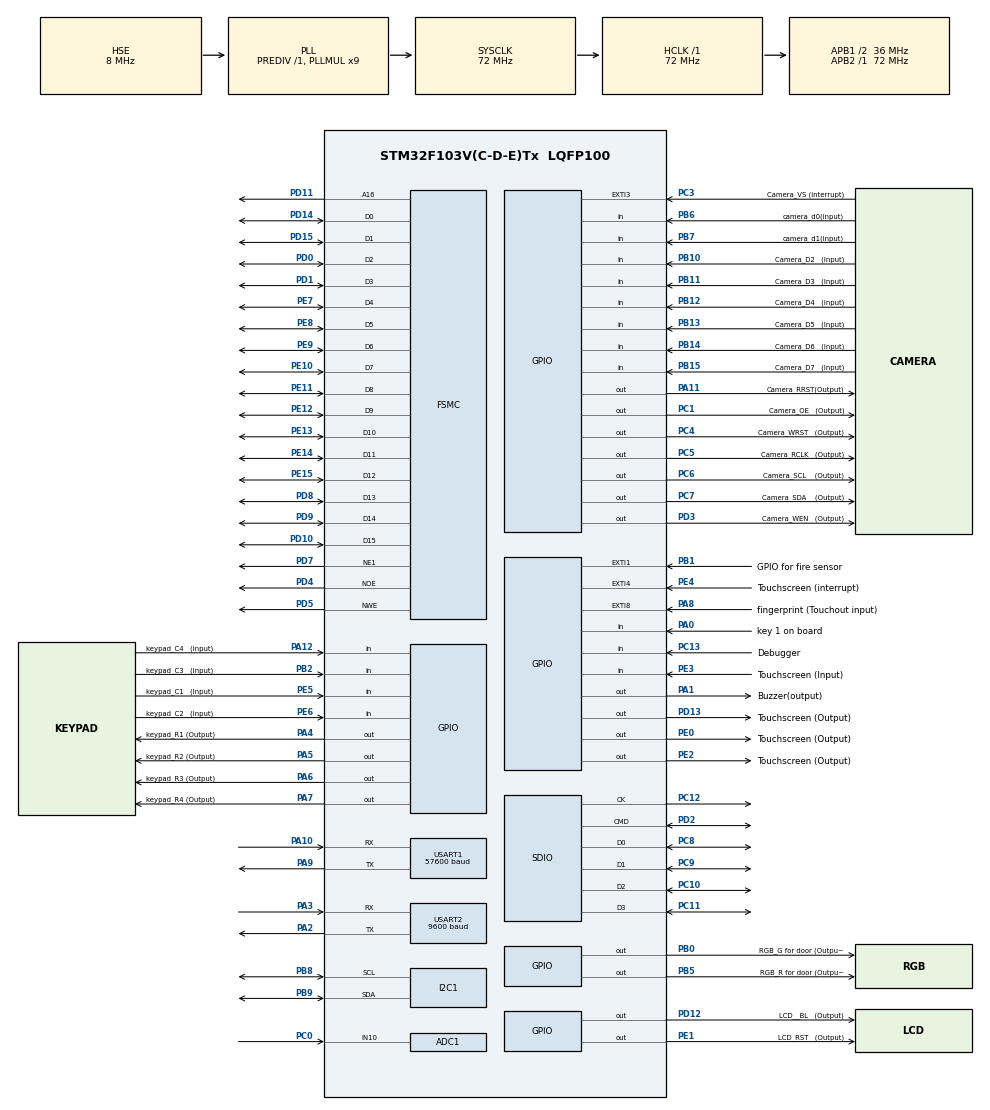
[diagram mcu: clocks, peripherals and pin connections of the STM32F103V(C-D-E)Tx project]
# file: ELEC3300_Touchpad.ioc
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ADC1.Channel-0\#ChannelRegularConversion=ADC_CHANNEL_10
ADC1.ContinuousConvMode=ENABLE
ADC1.EnableAnalogWatchDog=false
ADC1.NbrOfConversionFlag=1
ADC1.Rank-0\#ChannelRegularConversion=1
ADC1.SamplingTime-0\#ChannelRegularConversion=ADC_SAMPLETIME_55CYCLES_5
ADC1.master=1
FATFS._MAX_SS=4096
Mcu.Family=STM32F1
Mcu.Name=STM32F103V(C-D-E)Tx
Mcu.Package=LQFP100
NVIC.EXTI1_IRQn=true\:0\:0\:false\:false\:true\:true\:true
NVIC.EXTI3_IRQn=true\:0\:0\:false\:false\:true\:true\:true
NVIC.EXTI4_IRQn=true\:0\:0\:false\:false\:true\:true\:true
NVIC.EXTI9_5_IRQn=true\:1\:0\:true\:false\:true\:true\:true
NVIC.PriorityGroup=NVIC_PRIORITYGROUP_4
OSC_IN.Mode=HSE-External-Oscillator
OSC_IN.Signal=RCC_OSC_IN
OSC_OUT.Mode=HSE-External-Oscillator
OSC_OUT.Signal=RCC_OSC_OUT
PA0-WKUP.GPIO_Label=key 1 on board
PA0-WKUP.Signal=GPIO_Input
PA1.GPIO_Label=Buzzer(output)
PA1.GPIO_ModeDefaultOutputPP=GPIO_MODE_OUTPUT_PP
PA1.GPIO_PuPd=GPIO_NOPULL
PA1.GPIO_Speed=GPIO_SPEED_FREQ_HIGH
PA1.Signal=GPIO_Output
PA10.Mode=Asynchronous
PA10.Signal=USART1_RX
PA11.GPIO_Label=Camera_RRST(Output)
PA11.GPIO_Speed=GPIO_SPEED_FREQ_HIGH
PA11.PinState=GPIO_PIN_RESET
PA11.Signal=GPIO_Output
PA12.GPIO_Label=keypad_C4   (Input)
PA12.GPIO_PuPd=GPIO_PULLUP
PA12.Signal=GPIO_Input
PA13.Mode=Serial_Wire
PA13.Signal=SYS_JTMS-SWDIO
PA14.Mode=Serial_Wire
PA14.Signal=SYS_JTCK-SWCLK
PA2.Mode=Asynchronous
PA2.Signal=USART2_TX
PA3.Mode=Asynchronous
PA3.Signal=USART2_RX
PA4.GPIO_Label=keypad_R1 (Output)
PA4.Signal=GPIO_Output
PA5.GPIO_Label=keypad_R2 (Output)
PA5.Signal=GPIO_Output
PA6.GPIO_Label=keypad_R3 (Output)
PA6.Signal=GPIO_Output
PA7.GPIO_Label=keypad_R4 (Output)
PA7.Signal=GPIO_Output
PA8.GPIO_Label=fingerprint (Touchout input)
PA8.Signal=GPXTI8
PA9.Mode=Asynchronous
PA9.Signal=USART1_TX
PB0.GPIO_Label=RGB_G for door (Output)
PB0.GPIO_Speed=GPIO_SPEED_FREQ_HIGH
PB0.Signal=GPIO_Output
PB1.GPIO_Label=GPIO for fire sensor
PB1.GPIO_ModeDefaultEXTI=GPIO_MODE_IT_RISING_FALLING
PB1.Signal=GPXTI1
PB10.GPIO_Label=Camera_D2   (Input)
PB10.Signal=GPIO_Input
PB11.GPIO_Label=Camera_D3   (Input)
PB11.Signal=GPIO_Input
PB12.GPIO_Label=Camera_D4   (Input)
PB12.Signal=GPIO_Input
PB13.GPIO_Label=Camera_D5   (Input)
PB13.Signal=GPIO_Input
PB14.GPIO_Label=Camera_D6   (Input)
PB14.Signal=GPIO_Input
PB15.GPIO_Label=Camera_D7   (Input)
PB15.Signal=GPIO_Input
PB2.GPIO_Label=keypad_C3   (Input)
PB2.GPIO_PuPd=GPIO_PULLUP
PB2.Signal=GPIO_Input
PB5.GPIO_Label=RGB_R for door (Output)
PB5.GPIO_Speed=GPIO_SPEED_FREQ_HIGH
PB5.Signal=GPIO_Output
PB6.GPIO_Label=camera_d0(input)
PB6.Signal=GPIO_Input
PB7.GPIO_Label=camera_d1(input)
PB7.Signal=GPIO_Input
PB8.Mode=I2C
PB8.Signal=I2C1_SCL
PB9.Mode=I2C
PB9.Signal=I2C1_SDA
PC0.Signal=ADCx_IN10
PC1.GPIO_Label=Camera_OE   (Output)
PC1.GPIO_Speed=GPIO_SPEED_FREQ_HIGH
PC1.Signal=GPIO_Output
PC10.Mode=SD_4_bits_Wide_bus
PC10.Signal=SDIO_D2
PC11.Mode=SD_4_bits_Wide_bus
PC11.Signal=SDIO_D3
PC12.Mode=SD_4_bits_Wide_bus
PC12.Signal=SDIO_CK
PC13-TAMPER-RTC.GPIO_Label=Debugger
PC13-TAMPER-RTC.GPIO_PuPd=GPIO_NOPULL
PC13-TAMPER-RTC.Signal=GPIO_Input
PC14-OSC32_IN.Mode=LSE-External-Oscillator
PC14-OSC32_IN.Signal=RCC_OSC32_IN
PC15-OSC32_OUT.Mode=LSE-External-Oscillator
PC15-OSC32_OUT.Signal=RCC_OSC32_OUT
PC3.GPIO_Label=Camera_VS (interrupt)
PC3.GPIO_ModeDefaultEXTI=GPIO_MODE_IT_FALLING
PC3.Signal=GPXTI3
PC4.GPIO_Label=Camera_WRST   (Output)
PC4.GPIO_Speed=GPIO_SPEED_FREQ_HIGH
PC4.Signal=GPIO_Output
PC5.GPIO_Label=Camera_RCLK   (Output)
PC5.GPIO_Speed=GPIO_SPEED_FREQ_HIGH
PC5.Signal=GPIO_Output
PC6.GPIO_Label=Camera_SCL    (Output)
PC6.GPIO_ModeDefaultOutputPP=GPIO_MODE_OUTPUT_OD
PC6.GPIO_PuPd=GPIO_NOPULL
PC6.GPIO_Speed=GPIO_SPEED_FREQ_HIGH
PC6.Signal=GPIO_Output
PC7.GPIO_Label=Camera_SDA    (Output)
PC7.GPIO_ModeDefaultOutputPP=GPIO_MODE_OUTPUT_OD
PC7.GPIO_Speed=GPIO_SPEED_FREQ_HIGH
PC7.Signal=GPIO_Output
PC8.Mode=SD_4_bits_Wide_bus
PC8.Signal=SDIO_D0
PC9.Mode=SD_4_bits_Wide_bus
PC9.Signal=SDIO_D1
PD0.Mode=16b-d1
PD0.Signal=FSMC_D2
PD1.Mode=16b-d1
PD1.Signal=FSMC_D3
PD10.Mode=16b-d1
PD10.Signal=FSMC_D15
PD11.Mode=A16_1
PD11.Signal=FSMC_A16
PD12.GPIO_Label=LCD__BL   (Output)
PD12.GPIO_Speed=GPIO_SPEED_FREQ_HIGH
PD12.PinState=GPIO_PIN_RESET
PD12.Signal=GPIO_Output
PD13.GPIO_Label=Touchscreen (Output)
PD13.GPIO_Speed=GPIO_SPEED_FREQ_HIGH
PD13.Signal=GPIO_Output
PD14.Mode=16b-d1
PD14.Signal=FSMC_D0
PD15.Mode=16b-d1
PD15.Signal=FSMC_D1
PD2.Mode=SD_4_bits_Wide_bus
PD2.Signal=SDIO_CMD
PD3.GPIO_Label=Camera_WEN   (Output)
PD3.GPIO_Speed=GPIO_SPEED_FREQ_HIGH
PD3.Signal=GPIO_Output
PD4.Mode=Lcd1
PD4.Signal=FSMC_NOE
PD5.Mode=Lcd1
PD5.Signal=FSMC_NWE
PD7.Mode=NorPsramChipSelect1_1
PD7.Signal=FSMC_NE1
PD8.Mode=16b-d1
PD8.Signal=FSMC_D13
PD9.Mode=16b-d1
PD9.Signal=FSMC_D14
PE0.GPIO_Label=Touchscreen (Output)
PE0.GPIO_Speed=GPIO_SPEED_FREQ_HIGH
PE0.Signal=GPIO_Output
PE1.GPIO_Label=LCD_RST   (Output)
PE1.GPIO_Speed=GPIO_SPEED_FREQ_HIGH
PE1.PinState=GPIO_PIN_RESET
PE1.Signal=GPIO_Output
PE10.Mode=16b-d1
PE10.Signal=FSMC_D7
PE11.Mode=16b-d1
PE11.Signal=FSMC_D8
PE12.Mode=16b-d1
PE12.Signal=FSMC_D9
PE13.Mode=16b-d1
PE13.Signal=FSMC_D10
PE14.Mode=16b-d1
PE14.Signal=FSMC_D11
PE15.Mode=16b-d1
PE15.Signal=FSMC_D12
PE2.GPIO_Label=Touchscreen (Output)
PE2.GPIO_Speed=GPIO_SPEED_FREQ_HIGH
PE2.Signal=GPIO_Output
PE3.GPIO_Label=Touchscreen (Input)
PE3.GPIO_PuPd=GPIO_PULLUP
PE3.Signal=GPIO_Input
PE4.GPIO_Label=Touchscreen (interrupt)
PE4.GPIO_ModeDefaultEXTI=GPIO_MODE_IT_FALLING
PE4.GPIO_PuPd=GPIO_PULLUP
PE4.Signal=GPXTI4
PE5.GPIO_Label=keypad_C1   (Input)
PE5.GPIO_PuPd=GPIO_PULLUP
PE5.Signal=GPIO_Input
PE6.GPIO_Label=keypad_C2   (Input)
PE6.GPIO_PuPd=GPIO_PULLUP
PE6.Signal=GPIO_Input
PE7.Mode=16b-d1
PE7.Signal=FSMC_D4
PE8.Mode=16b-d1
PE8.Signal=FSMC_D5
PE9.Mode=16b-d1
PE9.Signal=FSMC_D6
ProjectManager.HeapSize=0x200
ProjectManager.StackSize=0x400
ProjectManager.TargetToolchain=MDK-ARM V5
RCC.ADCPresc=RCC_ADCPCLK2_DIV6
RCC.AHBFreq_Value=72000000
RCC.APB1CLKDivider=RCC_HCLK_DIV2
RCC.APB1Freq_Value=36000000
RCC.APB1TimFreq_Value=72000000
RCC.APB2Freq_Value=72000000
RCC.APB2TimFreq_Value=72000000
RCC.HCLKFreq_Value=72000000
RCC.PLLMUL=RCC_PLL_MUL9
RCC.PLLSourceVirtual=RCC_PLLSOURCE_HSE
RCC.SYSCLKFreq_VALUE=72000000
RCC.SYSCLKSource=RCC_SYSCLKSOURCE_PLLCLK
RCC.USBFreq_Value=72000000
SDIO.ClockDiv=4
SH.ADCx_IN10.0=ADC1_IN10,IN10
USART1.BaudRate=57600
USART1.StopBits=STOPBITS_1
USART1.VirtualMode=VM_ASYNC
USART2.BaudRate=9600
USART2.VirtualMode=VM_ASYNC
VP_FATFS_VS_SDIO.Mode=SDIO
board=custom

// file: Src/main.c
/* USER CODE BEGIN Header */
/**
  ******************************************************************************
  * @file           : main.c
  * @brief          : Main program body
  ******************************************************************************
  * @attention
  *
  * <h2><center>&copy; Copyright (c) 2022 STMicroelectronics.
  * All rights reserved.</center></h2>
  *
  * This software component is licensed by ST under Ultimate Liberty license
  * SLA0044, the "License"; You may not use this file except in compliance with
  * the License. You may obtain a copy of the License at:
  *                             www.st.com/SLA0044
  *
  ******************************************************************************
  */
/* USER CODE END Header */

#include "main.h"
#include "fatfs.h"

/* USER CODE BEGIN Includes */
#include "own_define_functions.h"
#include "as608.h"
#include <stdlib.h>
/* USER CODE END Includes */

ADC_HandleTypeDef hadc1;

I2C_HandleTypeDef hi2c1;

SD_HandleTypeDef hsd;

UART_HandleTypeDef huart1;
UART_HandleTypeDef huart2;

SRAM_HandleTypeDef hsram1;

/* USER CODE BEGIN PV */
volatile uint8_t FR_state = 0x00;
uint16_t current_id = 0x00;
/* USER CODE END PV */

void SystemClock_Config(void);
static void MX_GPIO_Init(void);
static void MX_FSMC_Init(void);
static void MX_SDIO_SD_Init(void);
static void MX_ADC1_Init(void);
static void MX_USART1_UART_Init(void);
static void MX_I2C1_Init(void);
static void MX_USART2_UART_Init(void);

int main(void)
{

  /* MCU Configuration--------------------------------------------------------*/

  /* Reset of all peripherals, Initializes the Flash interface and the Systick. */
  HAL_Init();

  /* Configure the system clock */
  SystemClock_Config();

  /* Initialize all configured peripherals */
  MX_GPIO_Init();
  MX_FSMC_Init();
  MX_SDIO_SD_Init();
  MX_FATFS_Init();
  MX_ADC1_Init();
  MX_USART1_UART_Init();
  MX_I2C1_Init();
  MX_USART2_UART_Init();
  /* USER CODE BEGIN 2 */
	macXPT2046_CS_DISABLE();
	delete_ALL();

	LCD_INIT();

	HAL_GPIO_WritePin(GPIOB, GPIO_PIN_0,GPIO_PIN_SET); // green off
	HAL_GPIO_WritePin(GPIOB, GPIO_PIN_5,GPIO_PIN_RESET); // red on

	//start page
	LCD_DrawString_Color(30, 100, "Home Protecting System", BACKGROUND, BLUE);
	HAL_Delay(4000);

	while( ! XPT2046_Touch_Calibrate () );   //calibrate TouchPad
	LCD_GramScan ( 1 );

	//set the password first
	LCD_Clear(0, 0, 240, 320, WHITE);
	LCD_DrawString_Color(10,10,"Please set a password with 4 places :", BACKGROUND, BLUE);
	enterPassword(password);
	LCD_DrawString_Color(10,150,"Password successfully set", BACKGROUND, BLUE);
	HAL_Delay(2000);

	//draw homepage
	LCD_homepage();
  /* USER CODE END 2 */

  /* Infinite loop */
  /* USER CODE BEGIN WHILE */
	//start co sensor in adc1
	HAL_ADCEx_Calibration_Start(&hadc1);
	HAL_ADC_Start(&hadc1);
	HAL_ADC_PollForConversion(&hadc1, 1000);

	while (1)
  {
		//if flame sensor detect flame. interrupt
		//if fingerprint sensor detect finger, interrupt

		//detect CO level in air, using polling
		CO_detect();
		//if user trigger #, check the password
		if(read_keypad() == '#'){
			verifyPassword(password, password_enter, &photoNum, &door_status);
			HAL_Delay(2000);
			LCD_homepage();
			continue;
		}

		//check homepage buttons
		if( ucXPT2046_TouchFlag == 1 ){
			check_homepage();
			ucXPT2046_TouchFlag = 0;
    }

		//close door after open for a while
		if (door_status == 1){
			HAL_GPIO_WritePin(GPIOB, GPIO_PIN_5,GPIO_PIN_SET);	//red off
			HAL_GPIO_WritePin(GPIOB, GPIO_PIN_0, GPIO_PIN_RESET);		//green on = door open
			HAL_Delay(10000);
			door_status = 0;
			HAL_GPIO_WritePin(GPIOB, GPIO_PIN_0,GPIO_PIN_SET); // green off
			HAL_GPIO_WritePin(GPIOB, GPIO_PIN_5,GPIO_PIN_RESET); // red on
		}

		//if door close with compass > 0 degree

		HAL_Delay(500);
    /* USER CODE END WHILE */

  }
}

void SystemClock_Config(void)
{
  RCC_OscInitTypeDef RCC_OscInitStruct = {0};
  RCC_ClkInitTypeDef RCC_ClkInitStruct = {0};
  RCC_PeriphCLKInitTypeDef PeriphClkInit = {0};

  /** Initializes the CPU, AHB and APB busses clocks
  */
  RCC_OscInitStruct.OscillatorType = RCC_OSCILLATORTYPE_HSE;
  RCC_OscInitStruct.HSEState = RCC_HSE_ON;
  RCC_OscInitStruct.HSEPredivValue = RCC_HSE_PREDIV_DIV1;
  RCC_OscInitStruct.HSIState = RCC_HSI_ON;
  RCC_OscInitStruct.PLL.PLLState = RCC_PLL_ON;
  RCC_OscInitStruct.PLL.PLLSource = RCC_PLLSOURCE_HSE;
  RCC_OscInitStruct.PLL.PLLMUL = RCC_PLL_MUL9;
  if (HAL_RCC_OscConfig(&RCC_OscInitStruct) != HAL_OK)
  {
    Error_Handler();
  }
  /** Initializes the CPU, AHB and APB busses clocks
  */
  RCC_ClkInitStruct.ClockType = RCC_CLOCKTYPE_HCLK|RCC_CLOCKTYPE_SYSCLK
                              |RCC_CLOCKTYPE_PCLK1|RCC_CLOCKTYPE_PCLK2;
  RCC_ClkInitStruct.SYSCLKSource = RCC_SYSCLKSOURCE_PLLCLK;
  RCC_ClkInitStruct.AHBCLKDivider = RCC_SYSCLK_DIV1;
  RCC_ClkInitStruct.APB1CLKDivider = RCC_HCLK_DIV2;
  RCC_ClkInitStruct.APB2CLKDivider = RCC_HCLK_DIV1;

  if (HAL_RCC_ClockConfig(&RCC_ClkInitStruct, FLASH_LATENCY_2) != HAL_OK)
  {
    Error_Handler();
  }
  PeriphClkInit.PeriphClockSelection = RCC_PERIPHCLK_ADC;
  PeriphClkInit.AdcClockSelection = RCC_ADCPCLK2_DIV6;
  if (HAL_RCCEx_PeriphCLKConfig(&PeriphClkInit) != HAL_OK)
  {
    Error_Handler();
  }
}

static void MX_ADC1_Init(void)
{

  ADC_ChannelConfTypeDef sConfig = {0};

  /** Common config
  */
  hadc1.Instance = ADC1;
  hadc1.Init.ScanConvMode = ADC_SCAN_DISABLE;
  hadc1.Init.ContinuousConvMode = ENABLE;
  hadc1.Init.DiscontinuousConvMode = DISABLE;
  hadc1.Init.ExternalTrigConv = ADC_SOFTWARE_START;
  hadc1.Init.DataAlign = ADC_DATAALIGN_RIGHT;
  hadc1.Init.NbrOfConversion = 1;
  if (HAL_ADC_Init(&hadc1) != HAL_OK)
  {
    Error_Handler();
  }
  /** Configure Regular Channel
  */
  sConfig.Channel = ADC_CHANNEL_10;
  sConfig.Rank = ADC_REGULAR_RANK_1;
  sConfig.SamplingTime = ADC_SAMPLETIME_55CYCLES_5;
  if (HAL_ADC_ConfigChannel(&hadc1, &sConfig) != HAL_OK)
  {
    Error_Handler();
  }

}

static void MX_I2C1_Init(void)
{

  hi2c1.Instance = I2C1;
  hi2c1.Init.ClockSpeed = 100000;
  hi2c1.Init.DutyCycle = I2C_DUTYCYCLE_2;
  hi2c1.Init.OwnAddress1 = 0;
  hi2c1.Init.AddressingMode = I2C_ADDRESSINGMODE_7BIT;
  hi2c1.Init.DualAddressMode = I2C_DUALADDRESS_DISABLE;
  hi2c1.Init.OwnAddress2 = 0;
  hi2c1.Init.GeneralCallMode = I2C_GENERALCALL_DISABLE;
  hi2c1.Init.NoStretchMode = I2C_NOSTRETCH_DISABLE;
  if (HAL_I2C_Init(&hi2c1) != HAL_OK)
  {
    Error_Handler();
  }

}

static void MX_SDIO_SD_Init(void)
{

  hsd.Instance = SDIO;
  hsd.Init.ClockEdge = SDIO_CLOCK_EDGE_RISING;
  hsd.Init.ClockBypass = SDIO_CLOCK_BYPASS_DISABLE;
  hsd.Init.ClockPowerSave = SDIO_CLOCK_POWER_SAVE_DISABLE;
  hsd.Init.BusWide = SDIO_BUS_WIDE_1B;
  hsd.Init.HardwareFlowControl = SDIO_HARDWARE_FLOW_CONTROL_DISABLE;
  hsd.Init.ClockDiv = 4;

}

static void MX_USART1_UART_Init(void)
{

  huart1.Instance = USART1;
  huart1.Init.BaudRate = 57600;
  huart1.Init.WordLength = UART_WORDLENGTH_8B;
  huart1.Init.StopBits = UART_STOPBITS_1;
  huart1.Init.Parity = UART_PARITY_NONE;
  huart1.Init.Mode = UART_MODE_TX_RX;
  huart1.Init.HwFlowCtl = UART_HWCONTROL_NONE;
  huart1.Init.OverSampling = UART_OVERSAMPLING_16;
  if (HAL_UART_Init(&huart1) != HAL_OK)
  {
    Error_Handler();
  }
  /* USER CODE BEGIN USART1_Init 2 */
	__HAL_UART_ENABLE_IT(&huart1, UART_IT_RXNE);
	__HAL_UART_ENABLE_IT(&huart1, UART_IT_IDLE);
  /* USER CODE END USART1_Init 2 */

}

static void MX_USART2_UART_Init(void)
{

  huart2.Instance = USART2;
  huart2.Init.BaudRate = 9600;
  huart2.Init.WordLength = UART_WORDLENGTH_8B;
  huart2.Init.StopBits = UART_STOPBITS_1;
  huart2.Init.Parity = UART_PARITY_NONE;
  huart2.Init.Mode = UART_MODE_TX_RX;
  huart2.Init.HwFlowCtl = UART_HWCONTROL_NONE;
  huart2.Init.OverSampling = UART_OVERSAMPLING_16;
  if (HAL_UART_Init(&huart2) != HAL_OK)
  {
    Error_Handler();
  }

}

static void MX_GPIO_Init(void)
{
  GPIO_InitTypeDef GPIO_InitStruct = {0};

  /* GPIO Ports Clock Enable */
  __HAL_RCC_GPIOE_CLK_ENABLE();
  __HAL_RCC_GPIOC_CLK_ENABLE();
  __HAL_RCC_GPIOA_CLK_ENABLE();
  __HAL_RCC_GPIOB_CLK_ENABLE();
  __HAL_RCC_GPIOD_CLK_ENABLE();

  /*Configure GPIO pin Output Level */
  HAL_GPIO_WritePin(GPIOE, Touchscreen_Pin|TouchscreenE0_Pin|LCD_RST_Pin, GPIO_PIN_RESET);

  /*Configure GPIO pin Output Level */
  HAL_GPIO_WritePin(GPIOC, Camera_OE_Pin|Camera_WRST_Pin|Camera_RCLK_Pin|Camera_SCL_Pin
                          |Camera_SDA_Pin, GPIO_PIN_RESET);

  /*Configure GPIO pin Output Level */
  HAL_GPIO_WritePin(GPIOA, Buzzer_Pin|keypad_R1_Pin|keypad_R2_Pin|keypad_R3_Pin
                          |keypad_R4_Pin|Camera_RRST_Pin, GPIO_PIN_RESET);

  /*Configure GPIO pin Output Level */
  HAL_GPIO_WritePin(GPIOB, RGB_G_for_door_Pin|RGB_R_for_door_Pin, GPIO_PIN_RESET);

  /*Configure GPIO pin Output Level */
  HAL_GPIO_WritePin(GPIOD, LCD__BL_Pin|TouchscreenD13_Pin|Camera_WEN_Pin, GPIO_PIN_RESET);

  /*Configure GPIO pins : Touchscreen_Pin TouchscreenE0_Pin LCD_RST_Pin */
  GPIO_InitStruct.Pin = Touchscreen_Pin|TouchscreenE0_Pin|LCD_RST_Pin;
  GPIO_InitStruct.Mode = GPIO_MODE_OUTPUT_PP;
  GPIO_InitStruct.Pull = GPIO_NOPULL;
  GPIO_InitStruct.Speed = GPIO_SPEED_FREQ_HIGH;
  HAL_GPIO_Init(GPIOE, &GPIO_InitStruct);

  /*Configure GPIO pins : TouchscreenE3_Pin keypad_C1_Pin keypad_C2_Pin */
  GPIO_InitStruct.Pin = TouchscreenE3_Pin|keypad_C1_Pin|keypad_C2_Pin;
  GPIO_InitStruct.Mode = GPIO_MODE_INPUT;
  GPIO_InitStruct.Pull = GPIO_PULLUP;
  HAL_GPIO_Init(GPIOE, &GPIO_InitStruct);

  /*Configure GPIO pin : TouchscreenE4_Pin */
  GPIO_InitStruct.Pin = TouchscreenE4_Pin;
  GPIO_InitStruct.Mode = GPIO_MODE_IT_FALLING;
  GPIO_InitStruct.Pull = GPIO_PULLUP;
  HAL_GPIO_Init(TouchscreenE4_GPIO_Port, &GPIO_InitStruct);

  /*Configure GPIO pin : Debugger_Pin */
  GPIO_InitStruct.Pin = Debugger_Pin;
  GPIO_InitStruct.Mode = GPIO_MODE_INPUT;
  GPIO_InitStruct.Pull = GPIO_NOPULL;
  HAL_GPIO_Init(Debugger_GPIO_Port, &GPIO_InitStruct);

  /*Configure GPIO pins : Camera_OE_Pin Camera_WRST_Pin Camera_RCLK_Pin */
  GPIO_InitStruct.Pin = Camera_OE_Pin|Camera_WRST_Pin|Camera_RCLK_Pin;
  GPIO_InitStruct.Mode = GPIO_MODE_OUTPUT_PP;
  GPIO_InitStruct.Pull = GPIO_NOPULL;
  GPIO_InitStruct.Speed = GPIO_SPEED_FREQ_HIGH;
  HAL_GPIO_Init(GPIOC, &GPIO_InitStruct);

  /*Configure GPIO pin : Camera_VS_Pin */
  GPIO_InitStruct.Pin = Camera_VS_Pin;
  GPIO_InitStruct.Mode = GPIO_MODE_IT_FALLING;
  GPIO_InitStruct.Pull = GPIO_NOPULL;
  HAL_GPIO_Init(Camera_VS_GPIO_Port, &GPIO_InitStruct);

  /*Configure GPIO pin : key_1_on_board_Pin */
  GPIO_InitStruct.Pin = key_1_on_board_Pin;
  GPIO_InitStruct.Mode = GPIO_MODE_INPUT;
  GPIO_InitStruct.Pull = GPIO_NOPULL;
  HAL_GPIO_Init(key_1_on_board_GPIO_Port, &GPIO_InitStruct);

  /*Configure GPIO pins : Buzzer_Pin Camera_RRST_Pin */
  GPIO_InitStruct.Pin = Buzzer_Pin|Camera_RRST_Pin;
  GPIO_InitStruct.Mode = GPIO_MODE_OUTPUT_PP;
  GPIO_InitStruct.Pull = GPIO_NOPULL;
  GPIO_InitStruct.Speed = GPIO_SPEED_FREQ_HIGH;
  HAL_GPIO_Init(GPIOA, &GPIO_InitStruct);

  /*Configure GPIO pins : keypad_R1_Pin keypad_R2_Pin keypad_R3_Pin keypad_R4_Pin */
  GPIO_InitStruct.Pin = keypad_R1_Pin|keypad_R2_Pin|keypad_R3_Pin|keypad_R4_Pin;
  GPIO_InitStruct.Mode = GPIO_MODE_OUTPUT_PP;
  GPIO_InitStruct.Pull = GPIO_NOPULL;
  GPIO_InitStruct.Speed = GPIO_SPEED_FREQ_LOW;
  HAL_GPIO_Init(GPIOA, &GPIO_InitStruct);

  /*Configure GPIO pins : RGB_G_for_door_Pin RGB_R_for_door_Pin */
  GPIO_InitStruct.Pin = RGB_G_for_door_Pin|RGB_R_for_door_Pin;
  GPIO_InitStruct.Mode = GPIO_MODE_OUTPUT_PP;
  GPIO_InitStruct.Pull = GPIO_NOPULL;
  GPIO_InitStruct.Speed = GPIO_SPEED_FREQ_HIGH;
  HAL_GPIO_Init(GPIOB, &GPIO_InitStruct);

  /*Configure GPIO pin : GPIO_for_fire_sensor_Pin */
  GPIO_InitStruct.Pin = GPIO_for_fire_sensor_Pin;
  GPIO_InitStruct.Mode = GPIO_MODE_IT_RISING_FALLING;
  GPIO_InitStruct.Pull = GPIO_NOPULL;
  HAL_GPIO_Init(GPIO_for_fire_sensor_GPIO_Port, &GPIO_InitStruct);

  /*Configure GPIO pin : keypad_C3_Pin */
  GPIO_InitStruct.Pin = keypad_C3_Pin;
  GPIO_InitStruct.Mode = GPIO_MODE_INPUT;
  GPIO_InitStruct.Pull = GPIO_PULLUP;
  HAL_GPIO_Init(keypad_C3_GPIO_Port, &GPIO_InitStruct);

  /*Configure GPIO pins : Camera_D2_Pin Camera_D3_Pin Camera_D4_Pin Camera_D5_Pin
                           Camera_D6_Pin Camera_D7_Pin camera_d0_Pin camera_d1_Pin */
  GPIO_InitStruct.Pin = Camera_D2_Pin|Camera_D3_Pin|Camera_D4_Pin|Camera_D5_Pin
                          |Camera_D6_Pin|Camera_D7_Pin|camera_d0_Pin|camera_d1_Pin;
  GPIO_InitStruct.Mode = GPIO_MODE_INPUT;
  GPIO_InitStruct.Pull = GPIO_NOPULL;
  HAL_GPIO_Init(GPIOB, &GPIO_InitStruct);

  /*Configure GPIO pins : LCD__BL_Pin TouchscreenD13_Pin Camera_WEN_Pin */
  GPIO_InitStruct.Pin = LCD__BL_Pin|TouchscreenD13_Pin|Camera_WEN_Pin;
  GPIO_InitStruct.Mode = GPIO_MODE_OUTPUT_PP;
  GPIO_InitStruct.Pull = GPIO_NOPULL;
  GPIO_InitStruct.Speed = GPIO_SPEED_FREQ_HIGH;
  HAL_GPIO_Init(GPIOD, &GPIO_InitStruct);

  /*Configure GPIO pins : Camera_SCL_Pin Camera_SDA_Pin */
  GPIO_InitStruct.Pin = Camera_SCL_Pin|Camera_SDA_Pin;
  GPIO_InitStruct.Mode = GPIO_MODE_OUTPUT_OD;
  GPIO_InitStruct.Pull = GPIO_NOPULL;
  GPIO_InitStruct.Speed = GPIO_SPEED_FREQ_HIGH;
  HAL_GPIO_Init(GPIOC, &GPIO_InitStruct);

  /*Configure GPIO pin : fingerprint_Pin */
  GPIO_InitStruct.Pin = fingerprint_Pin;
  GPIO_InitStruct.Mode = GPIO_MODE_IT_RISING;
  GPIO_InitStruct.Pull = GPIO_NOPULL;
  HAL_GPIO_Init(fingerprint_GPIO_Port, &GPIO_InitStruct);

  /*Configure GPIO pin : keypad_C4_Pin */
  GPIO_InitStruct.Pin = keypad_C4_Pin;
  GPIO_InitStruct.Mode = GPIO_MODE_INPUT;
  GPIO_InitStruct.Pull = GPIO_PULLUP;
  HAL_GPIO_Init(keypad_C4_GPIO_Port, &GPIO_InitStruct);

  /* EXTI interrupt init*/
  HAL_NVIC_SetPriority(EXTI1_IRQn, 0, 0);
  HAL_NVIC_EnableIRQ(EXTI1_IRQn);

  HAL_NVIC_SetPriority(EXTI3_IRQn, 0, 0);
  HAL_NVIC_EnableIRQ(EXTI3_IRQn);

  HAL_NVIC_SetPriority(EXTI4_IRQn, 0, 0);
  HAL_NVIC_EnableIRQ(EXTI4_IRQn);

  HAL_NVIC_SetPriority(EXTI9_5_IRQn, 1, 0);
  HAL_NVIC_EnableIRQ(EXTI9_5_IRQn);

}

/* FSMC initialization function */
static void MX_FSMC_Init(void)
{

  FSMC_NORSRAM_TimingTypeDef Timing = {0};

  /** Perform the SRAM1 memory initialization sequence
  */
  hsram1.Instance = FSMC_NORSRAM_DEVICE;
  hsram1.Extended = FSMC_NORSRAM_EXTENDED_DEVICE;
  /* hsram1.Init */
  hsram1.Init.NSBank = FSMC_NORSRAM_BANK1;
  hsram1.Init.DataAddressMux = FSMC_DATA_ADDRESS_MUX_DISABLE;
  hsram1.Init.MemoryType = FSMC_MEMORY_TYPE_SRAM;
  hsram1.Init.MemoryDataWidth = FSMC_NORSRAM_MEM_BUS_WIDTH_16;
  hsram1.Init.BurstAccessMode = FSMC_BURST_ACCESS_MODE_DISABLE;
  hsram1.Init.WaitSignalPolarity = FSMC_WAIT_SIGNAL_POLARITY_LOW;
  hsram1.Init.WrapMode = FSMC_WRAP_MODE_DISABLE;
  hsram1.Init.WaitSignalActive = FSMC_WAIT_TIMING_BEFORE_WS;
  hsram1.Init.WriteOperation = FSMC_WRITE_OPERATION_ENABLE;
  hsram1.Init.WaitSignal = FSMC_WAIT_SIGNAL_DISABLE;
  hsram1.Init.ExtendedMode = FSMC_EXTENDED_MODE_DISABLE;
  hsram1.Init.AsynchronousWait = FSMC_ASYNCHRONOUS_WAIT_DISABLE;
  hsram1.Init.WriteBurst = FSMC_WRITE_BURST_DISABLE;
  /* Timing */
  Timing.AddressSetupTime = 15;
  Timing.AddressHoldTime = 15;
  Timing.DataSetupTime = 255;
  Timing.BusTurnAroundDuration = 15;
  Timing.CLKDivision = 16;
  Timing.DataLatency = 17;
  Timing.AccessMode = FSMC_ACCESS_MODE_A;
  /* ExtTiming */

  if (HAL_SRAM_Init(&hsram1, &Timing, NULL) != HAL_OK)
  {
    Error_Handler( );
  }

  /** Disconnect NADV
  */

  __HAL_AFIO_FSMCNADV_DISCONNECTED();

}

void Error_Handler(void)
{
}

/************************ (C) COPYRIGHT STMicroelectronics *****END OF FILE****/
